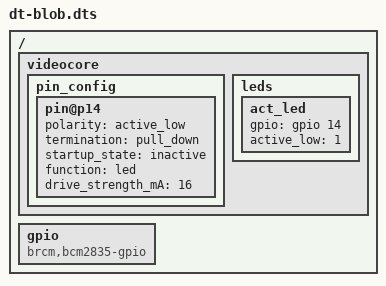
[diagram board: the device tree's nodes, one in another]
/dts-v1/;
/{
  videocore {
    pin_config {
      pin@p14 {
        polarity = "active_low";          // Adjust as needed
        termination = "pull_down";       // Use pull_down or pull_up if required
        startup_state = "inactive";      // Initial state of the pin
        function = "led";                // Designate this pin as an LED function
        drive_strength_mA = <16>;        // Current drive strength
      };
    };

    leds {
      act_led {
        gpio = <&gpio 14 0>;             // Reference the GPIO node for GPIO14
        active_low = <1>;                // Set active_low if your LED logic is inverted
      };
    };
  };

  gpio: gpio {
    compatible = "brcm,bcm2835-gpio";    // Add the GPIO controller compatible string
  };
};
